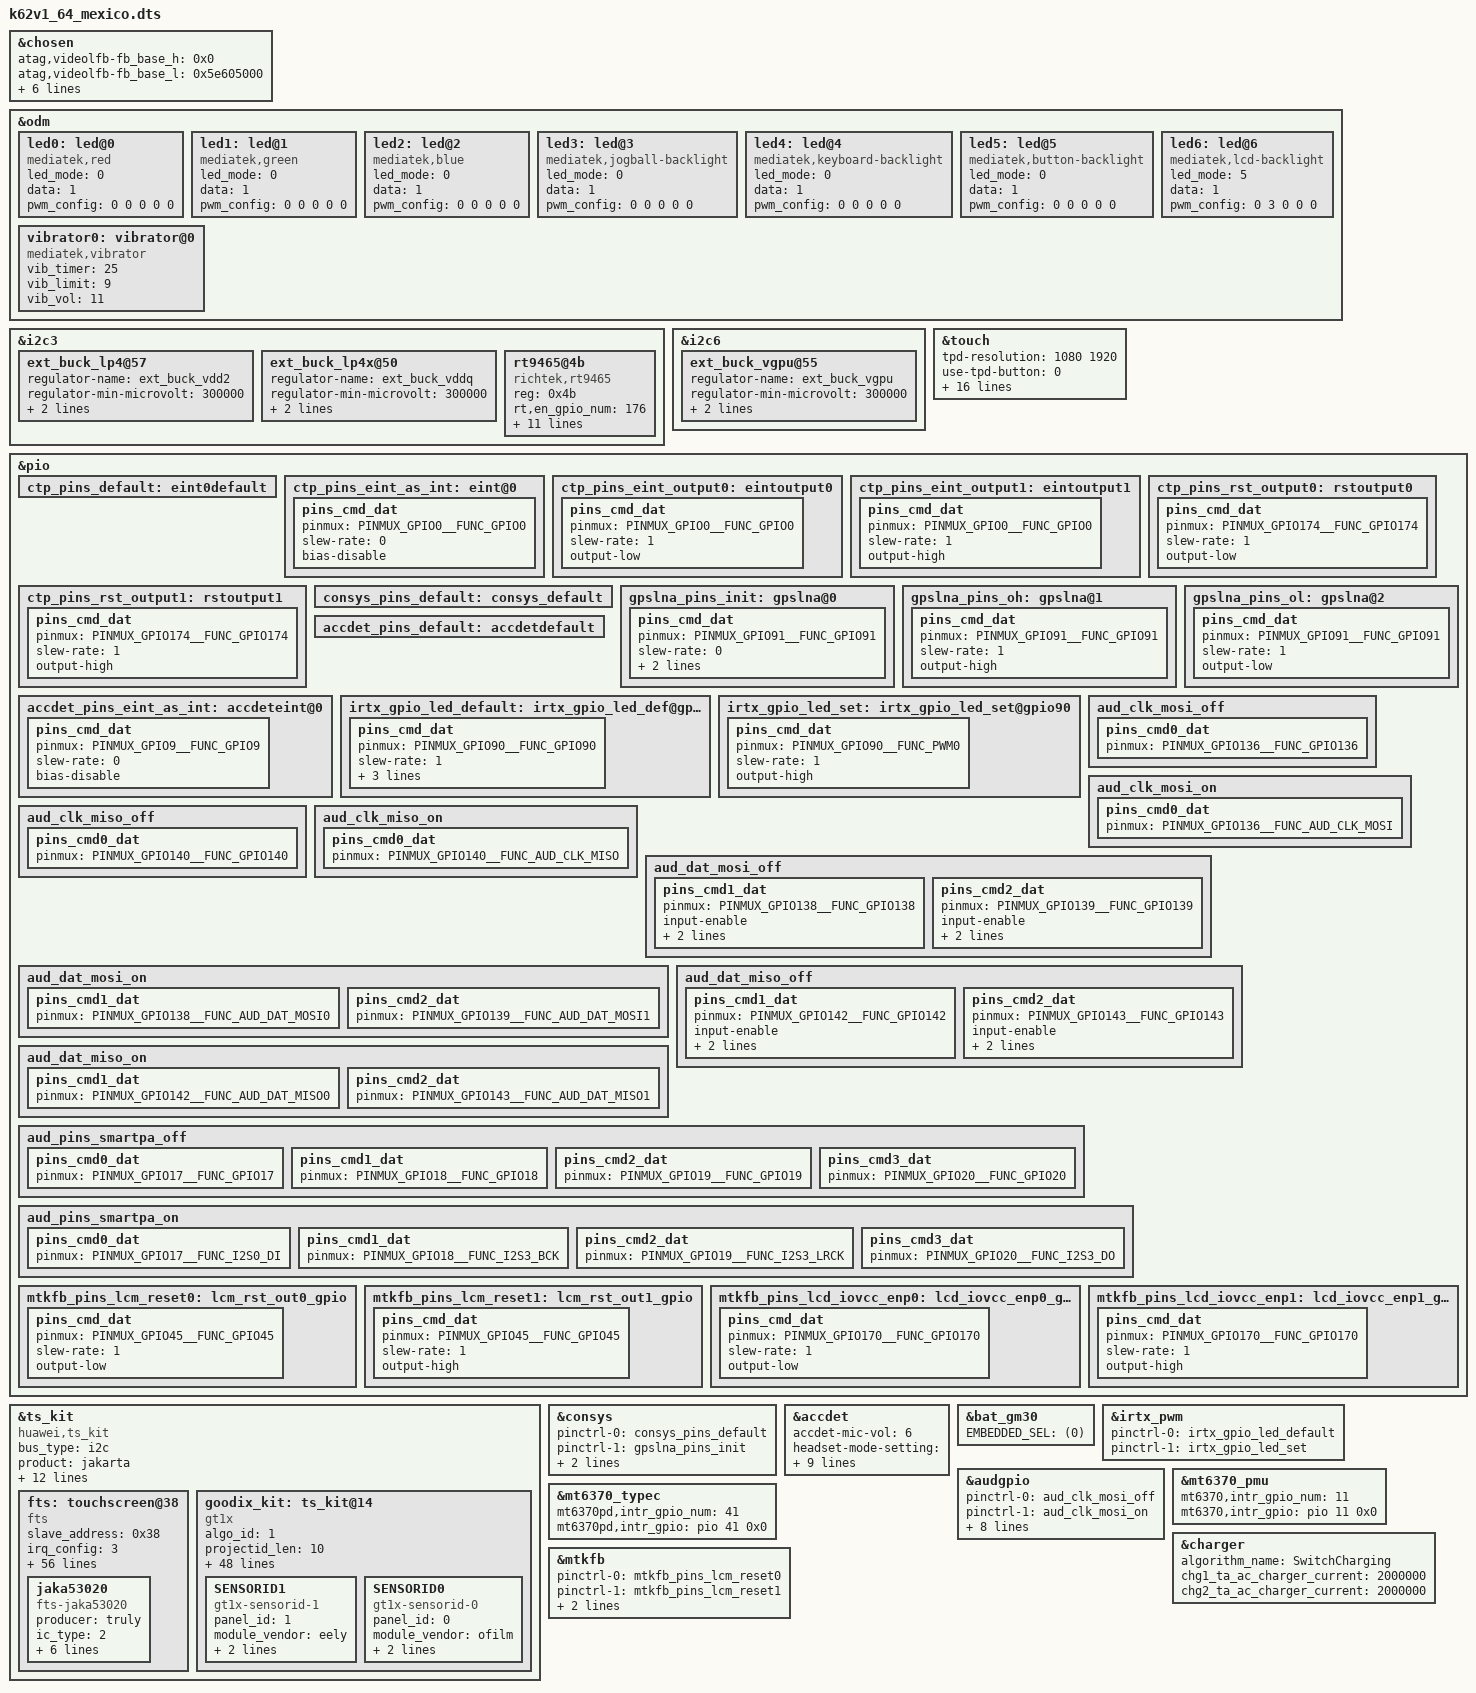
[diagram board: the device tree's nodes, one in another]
#include <dt-bindings/interrupt-controller/arm-gic.h>
#include <dt-bindings/interrupt-controller/irq.h>
#include <dt-bindings/pinctrl/mt6765-pinfunc.h>
#include <dt-bindings/clock/mt6765-clk.h>

/dts-v1/;
/plugin/;

#include "huawei-wifi.dtsi"

/* chosen */
&chosen {

	/* fpga may has no lk, we need to specify display info here */
	/* fb buffer is reserved using this dts by memory node above */
	atag,videolfb-fb_base_h = <0x0>;
	atag,videolfb-fb_base_l = <0x5e605000>;
	atag,videolfb-islcmfound = <1>;
	/* because no lk, so lcm is not inited */
	atag,videolfb-islcm_inited = <0>;
	atag,videolfb-fps= <6000>;
	atag,videolfb-vramSize= <0x017bb000>;
	atag,videolfb-lcmname= "nt35695B_fhd_dsi_cmd_auo_rt5081_drv";
};

&odm {
	led0:led@0 {
		compatible = "mediatek,red";
		led_mode = <0>;
		data = <1>;
		pwm_config = <0 0 0 0 0>;
	};
	led1:led@1 {
		compatible = "mediatek,green";
		led_mode = <0>;
		data = <1>;
		pwm_config = <0 0 0 0 0>;
	};
	led2:led@2 {
		compatible = "mediatek,blue";
		led_mode = <0>;
		data = <1>;
		pwm_config = <0 0 0 0 0>;
	};
	led3:led@3 {
		compatible = "mediatek,jogball-backlight";
		led_mode = <0>;
		data = <1>;
		pwm_config = <0 0 0 0 0>;
	};
	led4:led@4 {
		compatible = "mediatek,keyboard-backlight";
		led_mode = <0>;
		data = <1>;
		pwm_config = <0 0 0 0 0>;
	};
	led5:led@5 {
		compatible = "mediatek,button-backlight";
		led_mode = <0>;
		data = <1>;
		pwm_config = <0 0 0 0 0>;
	};
	led6:led@6 {
		compatible = "mediatek,lcd-backlight";
		led_mode = <5>;
		data = <1>;
		pwm_config = <0 3 0 0 0>;
	};
	vibrator0:vibrator@0 {
		compatible = "mediatek,vibrator";
		vib_timer = <25>;
		vib_limit = <9>;
		vib_vol= <11>;
	};
};

&i2c3 {
	ext_buck_lp4@57 {
		regulator-name ="ext_buck_vdd2";
		regulator-min-microvolt = <300000>;
		regulator-max-microvolt = <1300000>;
		vsel_pin = <0>;
	};

	ext_buck_lp4x@50 {
		regulator-name ="ext_buck_vddq";
		regulator-min-microvolt = <300000>;
		regulator-max-microvolt = <1300000>;
		vsel_pin = <1>;
	};
};

&i2c6 {
	ext_buck_vgpu@55 {
		regulator-name ="ext_buck_vgpu";
		regulator-min-microvolt = <300000>;
		regulator-max-microvolt = <1300000>;
		vsel_pin = <2>;
	};
};
/* TOUCH start */
&touch {
	tpd-resolution = <1080 1920>;
	use-tpd-button = <0>;
	tpd-key-num = <3>;
	tpd-key-local= <139 172 158 0>;
	tpd-key-dim-local = <90 883 100 40 230
				 883 100 40 370 883 100 40 0 0 0 0>;
	tpd-max-touch-num = <5>;
	tpd-filter-enable = <1>;
	tpd-filter-pixel-density = <146>;
	tpd-filter-custom-prameters = <0 0 0 0 0 0 0 0 0 0 0 0>;
	tpd-filter-custom-speed = <0 0 0>;
	pinctrl-names = "default", "state_eint_as_int", "state_eint_output0",
		"state_eint_output1", "state_rst_output0", "state_rst_output1";
	pinctrl-0 = <&ctp_pins_default>;
	pinctrl-1 = <&ctp_pins_eint_as_int>;
	pinctrl-2 = <&ctp_pins_eint_output0>;
	pinctrl-3 = <&ctp_pins_eint_output1>;
	pinctrl-4 = <&ctp_pins_rst_output0>;
	pinctrl-5 = <&ctp_pins_rst_output1>;
	status = "okay";
};
&pio {
	ctp_pins_default: eint0default {
	};
	ctp_pins_eint_as_int: eint@0 {
		pins_cmd_dat {
			pinmux = <PINMUX_GPIO0__FUNC_GPIO0>;
			slew-rate = <0>;
			bias-disable;
		};
	};
	ctp_pins_eint_output0: eintoutput0 {
		pins_cmd_dat {
			pinmux = <PINMUX_GPIO0__FUNC_GPIO0>;
			slew-rate = <1>;
			output-low;
		};
	};
	ctp_pins_eint_output1: eintoutput1 {
		pins_cmd_dat {
			pinmux = <PINMUX_GPIO0__FUNC_GPIO0>;
			slew-rate = <1>;
			output-high;
		};
	};
	ctp_pins_rst_output0: rstoutput0 {
		pins_cmd_dat {
			pinmux = <PINMUX_GPIO174__FUNC_GPIO174>;
			slew-rate = <1>;
			output-low;
		};
	};
	ctp_pins_rst_output1: rstoutput1 {
		pins_cmd_dat {
			pinmux = <PINMUX_GPIO174__FUNC_GPIO174>;
			slew-rate = <1>;
			output-high;
		};
	};
};
&ts_kit {
	status = "okay";
	compatible = "huawei,ts_kit";	/* Do not change value*/
	bus_type = "i2c";
	product = "jakarta";
	bus_id = <0>;
	has_virtualkey = <0>;
	debounce = <6 0>;
	interrupt-parent = <&pio>;
	interrupts = <0 2 0 0>;
	aft_enable = <0>;		/* aft algo switch. 1 - enabel, 0 - disable*/
	drv_stop_width = <0>;	/* always 0, can not config */
	lcd_width = <0>;		/* always 0, can not config */
	lcd_height = <0>;		/* always 0, can not config */
	need_i2c_hwlock = <0>;	/* for i2c both used by ap and sensorhub */
	register_charger_notifier = <0>;
	hide_plain_id = <0>;

	fts: touchscreen@38 {
		compatible = "fts";

		/* ts chip common config, parsed by paltform */
		/* hardware config part */
		slave_address = <0x38>;
		irq_config = <3>;

		/* base config */
		projectid_len = <10>; /* default 10 */
		ic_type = <2>;

		/* power config part */
		power_self_ctrl = <1>;
		ts-kit-iovdd-type = <1>;
		ts-kit-vcc-type = <1>;
		ts-kit-iovdd-value = <1800000>;
		ts-kit-vcc-value = <3000000>;
		vddio_default_on = <1>;
		ts-kit-iovdd-supply = <&mt_pmic_vs1_buck_reg>;  /* TODO:need parse by platform */
		ts-kit-vcc-supply = <&mt_pmic_vldo28_ldo_reg>; /* TODO:need parse by platform */

		/* pinctl config part */
		pinctrl-names = "default", "state_eint_as_int", "state_eint_output0",
			"state_eint_output1", "state_rst_output0", "state_rst_output1";
		pinctrl-0 = <&ctp_pins_default>;
		pinctrl-1 = <&ctp_pins_eint_as_int>;
		pinctrl-2 = <&ctp_pins_eint_output0>;
		pinctrl-3 = <&ctp_pins_eint_output1>;
		pinctrl-4 = <&ctp_pins_rst_output0>;
		pinctrl-5 = <&ctp_pins_rst_output1>;

		/* input config part */
		x_max = <720>;
		y_max = <1560>;
		x_max_mt = <720>;
		y_max_mt = <1560>;
		flip_x = <1>;
		flip_y = <1>;

		/* feature config part */
		parade,is_parade_solution = <0>;
		parade,direct_proc_cmd = <0>;
		parade,sleep_in_mode = <0>;
		roi_supported = <0>;
		glove_supported = <0>;
		holster_supported = <0>;
		pen_support = <0>;
		support_3d_func = <0>;
		charger_supported = <0>;
		check_bulcked = <0>;
		support_aft = <0>;
		use_lcdkit_power_notify = <1>;
		fp_tp_report_touch_minor_event = <0>;
		algo_id = <1>; /* 0 - not use driver algo 1 - algo t1 */
		need_wd_check_status = <0>;
		check_status_watchdog_timeout = <0>;
		touch_switch_flag = <0>;
		get_brightness_info_flag = <0>;
		has_virtualkey = <0>;
		lcd_full = <0>;
		provide_panel_id_support = <0>;
		chip_id = <0x54>;
		hard_reset_delay = <200>;
		erase_min_delay = <1350>;
		calc_crc_delay = <300>;
		reboot_delay = <300>;
		erase_query_delay = <50>;
		write_flash_query_times = <30>;
		read_ecc_query_times = <100>;
		erase_flash_query_times = <15>;
		upgrade_loop_times = <5>;
		pram_projectid_addr = <0xd7a0>;
		rawdata_newformatflag = <1>;
		only_open_once_captest_threshold = <1>;
		jaka53020{
			producer = "truly";
			ic_type = <2>;
			compatible = "fts-jaka53020";
			row_column_delta_test = <0>;
			lcd_noise_data_test = <1>;
			row_column_delta_test_point_by_point = <1>;
			threshold,point_by_point_judge = <1>;
			threshold,in_csv_file = <1>;
			provide_panel_id_suppot = <1>;

			/* chip private config */
		};
	};
	goodix_kit: ts_kit@14 {
		compatible = "gt1x";
		algo_id = <1>;
		projectid_len = <10>; /* default 10 */

		/* pinctl config part */
		pinctrl-names = "default", "state_eint_as_int", "state_eint_output0",
			"state_eint_output1", "state_rst_output0", "state_rst_output1";
		pinctrl-0 = <&ctp_pins_default>;
		pinctrl-1 = <&ctp_pins_eint_as_int>;
		pinctrl-2 = <&ctp_pins_eint_output0>;
		pinctrl-3 = <&ctp_pins_eint_output1>;
		pinctrl-4 = <&ctp_pins_rst_output0>;
		pinctrl-5 = <&ctp_pins_rst_output1>;

		/* input config part */
		x_max = <720>;
		y_max = <1560>;
		x_max_mt = <720>;
		y_max_mt = <1560>;
		flip_x = <1>;
		flip_y = <1>;

		/* power config part */
		power_self_ctrl = <1>;
		ts-kit-iovdd-type = <1>;
		ts-kit-vcc-type = <1>;
		ts-kit-iovdd-value = <1800000>;
		ts-kit-vcc-value = <3000000>;
		vddio_default_on = <1>;
		ts-kit-iovdd-supply = <&mt_pmic_vs1_buck_reg>;  /* TODO:need parse by platform */
		ts-kit-vcc-supply = <&mt_pmic_vldo28_ldo_reg>; /* TODO:need parse by platform */

		slave_address = <0x14>;
		irq_config = <3>;/* 0 - LOW LEVEL  1 - HIGH LEVEL  2 - RAISE EDGE  3 - FALL EDGE*/

		roi_data_size = <7 7>; /* row and colume*/
		project_id = "JAKA54000";
		chip_name = "1158"; /* GT1151Q */
		module_vendor = "ofilm";

		rawdata_newformatflag = <1>;
		/* feature config part */
		parade,is_parade_solution = <0>;
		parade,direct_proc_cmd = <0>;
		parade,sleep_in_mode = <0>;
		roi_supported = <0>;
		glove_supported = <0>;
		holster_supported = <0>;
		pen_support = <0>;
		support_3d_func = <0>;
		charger_supported = <0>;
		check_bulcked = <0>;
		support_aft = <0>;
		tools_support = <1>; /* support GTP tools APK ,0:no support; 1: support*/
		easy_wakeup_supported = <0>;
		ic_type = <0>; /* 0: 9PT, 1: 9P*/
		gt1x_test_limit = <1>;
		use_lcdkit_power_notify = <1>;
		support_get_tp_color = <0>;
		fw_only_depend_on_lcd = <0>;
		gt1x_edge_add = <0x81A1>;
		gt1x_support_edge_xyer = <1>;
		only_open_once_captest_threshold = <1>;
		SENSORID1 {
			compatible = "gt1x-sensorid-1";
			panel_id = <1>;
			module_vendor = "eely";
			provide_panel_id_suppot = <1>;
			project_id = "JAKA54010";
		};
		SENSORID0 {
			compatible = "gt1x-sensorid-0";
			panel_id = <0>;
			module_vendor = "ofilm";
			provide_panel_id_suppot = <1>;
			project_id = "JAKA54000";
		};
	};
};
/* TOUCH end */

/* CONSYS GPIO standardization */
&pio {
	consys_pins_default: consys_default {
	};
	gpslna_pins_init: gpslna@0 {
		pins_cmd_dat {
			pinmux = <PINMUX_GPIO91__FUNC_GPIO91>;
			slew-rate = <0>;
			bias-disable;
			output-low;
		};
	};
	gpslna_pins_oh: gpslna@1 {
		pins_cmd_dat {
			pinmux = <PINMUX_GPIO91__FUNC_GPIO91>;
			slew-rate = <1>;
			output-high;
		};
	};
	gpslna_pins_ol: gpslna@2 {
		pins_cmd_dat {
			pinmux = <PINMUX_GPIO91__FUNC_GPIO91>;
			slew-rate = <1>;
			output-low;
		};
	};
};
&consys {
	pinctrl-names = "default", "gps_lna_state_init",
		"gps_lna_state_oh", "gps_lna_state_ol";
	pinctrl-0 = <&consys_pins_default>;
	pinctrl-1 = <&gpslna_pins_init>;
	pinctrl-2 = <&gpslna_pins_oh>;
	pinctrl-3 = <&gpslna_pins_ol>;
	status = "okay";
};
/* CONSYS end */

/* accdet start */
&accdet {
	accdet-mic-vol = <6>;
	headset-mode-setting = <0x500 0x500 1 0x1f0 0x800 0x800 0x20 0x44>;
	accdet-plugout-debounce = <1>;
	accdet-mic-mode = <1>;
	headset-eint-level-pol = <8>;
	headset-three-key-threshold = <0 80 220 400>;
	headset-three-key-threshold-CDD = <0 121 192 600>;
	headset-four-key-threshold = <0 58 121 192 400>;
	pinctrl-names = "default", "state_eint_as_int";
	pinctrl-0 = <&accdet_pins_default>;
	pinctrl-1 = <&accdet_pins_eint_as_int>;
	status = "okay";
};
&pio {
	accdet_pins_default: accdetdefault {
	};
	accdet_pins_eint_as_int: accdeteint@0 {
		pins_cmd_dat {
			pinmux = <PINMUX_GPIO9__FUNC_GPIO9>;
			slew-rate = <0>;
			bias-disable;
		};
	};
};
/* accdet end */

/* FINGERPRINT start */
/*
&spi0 {
	#address-cells = <1>;
	#size-cells = <0>;
	fingerprint@0 {
		compatible = "goodix,goodix-fp";
		reg = <0>;
		spi-max-frequency = <8000000>;
		netlink-event = <30>;
		status = "okay";
	};
};

&goodix_fp {
	pinctrl-names = "default", "reset_high", "reset_low";
	pinctrl-0 = <&fingerprint_default>;
	pinctrl-1 = <&fingerprint_reset_high>;
	pinctrl-2 = <&fingerprint_reset_low>;
	status = "okay";
};

&pio {
	fingerprint_default: state_default {
	};
	fingerprint_reset_high: state_reset_high {
		pins_cmd_dat {
			pinmux = <PINMUX_GPIO172__FUNC_GPIO172>;
			slew-rate = <1>;
			output-high;
		};
	};
	fingerprint_reset_low: state_reset_low {
		pins_cmd_dat {
			pinmux = <PINMUX_GPIO172__FUNC_GPIO172>;
			slew-rate = <1>;
			output-low;
		};
	};
};*/
/* FINGERPRINT end */

/* battery end */
&bat_gm30 {
	EMBEDDED_SEL = <(0)>;
};
/* battery end */

/* IRTX GPIO end */
&irtx_pwm {
	pinctrl-names = "irtx_gpio_led_default", "irtx_gpio_led_set";
	pinctrl-0 = <&irtx_gpio_led_default>;
	pinctrl-1 = <&irtx_gpio_led_set>;
	status = "okay";
};
&pio {
	irtx_gpio_led_default:irtx_gpio_led_def@gpio90 {
		pins_cmd_dat {
			pinmux = <PINMUX_GPIO90__FUNC_GPIO90>;
			slew-rate = <1>;
			bias-disable;
			output-low;
			input-schmitt-enable = <0>;
		};
	};

	irtx_gpio_led_set:irtx_gpio_led_set@gpio90 {
		pins_cmd_dat {
			pinmux = <PINMUX_GPIO90__FUNC_PWM0>;
			slew-rate = <1>;
			output-high;
		};
	};
};
/* IRTX GPIO Settings -End */

/* AUDIO GPIO standardization */
&audgpio {
	pinctrl-names = "aud_clk_mosi_off",
			"aud_clk_mosi_on",
			"aud_clk_miso_off",
			"aud_clk_miso_on",
			"aud_dat_mosi_off",
			"aud_dat_mosi_on",
			"aud_dat_miso_off",
			"aud_dat_miso_on",
			"aud_smartpa_off",
			"aud_smartpa_on";
	pinctrl-0 = <&aud_clk_mosi_off>;
	pinctrl-1 = <&aud_clk_mosi_on>;
	pinctrl-2 = <&aud_clk_miso_off>;
	pinctrl-3 = <&aud_clk_miso_on>;
	pinctrl-4 = <&aud_dat_mosi_off>;
	pinctrl-5 = <&aud_dat_mosi_on>;
	pinctrl-6 = <&aud_dat_miso_off>;
	pinctrl-7 = <&aud_dat_miso_on>;
	pinctrl-8 = <&aud_pins_smartpa_off>;
	pinctrl-9 = <&aud_pins_smartpa_on>;
	status = "okay";
};

&pio {
	aud_clk_mosi_off: aud_clk_mosi_off {
		pins_cmd0_dat {
			pinmux = <PINMUX_GPIO136__FUNC_GPIO136>;
		};
	};

	aud_clk_mosi_on: aud_clk_mosi_on {
		pins_cmd0_dat {
			pinmux = <PINMUX_GPIO136__FUNC_AUD_CLK_MOSI>;
		};
	};

	aud_clk_miso_off: aud_clk_miso_off {
		pins_cmd0_dat {
			pinmux = <PINMUX_GPIO140__FUNC_GPIO140>;
		};
	};

	aud_clk_miso_on: aud_clk_miso_on {
		pins_cmd0_dat {
			pinmux = <PINMUX_GPIO140__FUNC_AUD_CLK_MISO>;
		};
	};

	aud_dat_mosi_off: aud_dat_mosi_off {
		pins_cmd1_dat {
			pinmux = <PINMUX_GPIO138__FUNC_GPIO138>;
			input-enable;
			slew-rate = <0>;
			bias-disable;
		};
		pins_cmd2_dat {
			pinmux = <PINMUX_GPIO139__FUNC_GPIO139>;
			input-enable;
			slew-rate = <0>;
			bias-disable;
		};
	};

	aud_dat_mosi_on: aud_dat_mosi_on {
		pins_cmd1_dat {
			pinmux = <PINMUX_GPIO138__FUNC_AUD_DAT_MOSI0>;
		};
		pins_cmd2_dat {
			pinmux = <PINMUX_GPIO139__FUNC_AUD_DAT_MOSI1>;
		};
	};

	aud_dat_miso_off: aud_dat_miso_off {
		pins_cmd1_dat {
			pinmux = <PINMUX_GPIO142__FUNC_GPIO142>;
			input-enable;
			slew-rate = <0>;
			bias-disable;
		};
		pins_cmd2_dat {
			pinmux = <PINMUX_GPIO143__FUNC_GPIO143>;
			input-enable;
			slew-rate = <0>;
			bias-disable;
		};
	};

	aud_dat_miso_on: aud_dat_miso_on {
		pins_cmd1_dat {
			pinmux = <PINMUX_GPIO142__FUNC_AUD_DAT_MISO0>;
		};
		pins_cmd2_dat {
			pinmux = <PINMUX_GPIO143__FUNC_AUD_DAT_MISO1>;
		};
	};

	aud_pins_smartpa_off: aud_pins_smartpa_off {
		pins_cmd0_dat {
			pinmux = <PINMUX_GPIO17__FUNC_GPIO17>;
		};
		pins_cmd1_dat {
			pinmux = <PINMUX_GPIO18__FUNC_GPIO18>;
		};
		pins_cmd2_dat {
			pinmux = <PINMUX_GPIO19__FUNC_GPIO19>;
		};
		pins_cmd3_dat {
			pinmux = <PINMUX_GPIO20__FUNC_GPIO20>;
		};
	};

	aud_pins_smartpa_on: aud_pins_smartpa_on {
		pins_cmd0_dat {
			pinmux = <PINMUX_GPIO17__FUNC_I2S0_DI>;
		};
		pins_cmd1_dat {
			pinmux = <PINMUX_GPIO18__FUNC_I2S3_BCK>;
		};
		pins_cmd2_dat {
			pinmux = <PINMUX_GPIO19__FUNC_I2S3_LRCK>;
		};
		pins_cmd3_dat {
			pinmux = <PINMUX_GPIO20__FUNC_I2S3_DO>;
		};
	};
};
/* AUDIO end */

&mt6370_pmu {
	mt6370,intr_gpio_num = <11>; /* direct defined GPIO num */
	mt6370,intr_gpio = <&pio 11 0x0>;
};

&mt6370_typec {
	mt6370pd,intr_gpio_num = <41>; /* direct defined GPIO num */
	mt6370pd,intr_gpio = <&pio 41 0x0>;
};

&charger {
	algorithm_name = "SwitchCharging";
	chg1_ta_ac_charger_current = <2000000>;
	chg2_ta_ac_charger_current = <2000000>;
};

&i2c3 {
	rt9465@4b {
		compatible = "richtek,rt9465";
		reg = <0x4b>;
		status = "okay";
		rt,en_gpio_num = <176>;
		rt,en_gpio = <&pio 176 0x0>;
		rt,intr_gpio_num = <23>; /* direct defined GPIO num */
		rt,intr_gpio = <&pio 23 0x0>;
		interrupt-names = "wdtmri";
		charger_name = "secondary_chg";
		ichg = <1500000>; /* uA */
		mivr = <4500000>; /* uV */
		cv = <4550000>; /* uV */
		ieoc = <700000>; /* uA */
		safety_timer = <12>; /* hour */
		en_st; /* safety timer */
		/* en_te; */
		en_wdt;
	};
};


/* DISPSYS GPIO standardization */
&pio {
	mtkfb_pins_lcm_reset0: lcm_rst_out0_gpio {
		pins_cmd_dat {
			pinmux = <PINMUX_GPIO45__FUNC_GPIO45>;
			slew-rate = <1>;
			output-low;
		};
	};

	mtkfb_pins_lcm_reset1: lcm_rst_out1_gpio {
		pins_cmd_dat {
			pinmux = <PINMUX_GPIO45__FUNC_GPIO45>;
			slew-rate = <1>;
			output-high;
		};
	};

	mtkfb_pins_lcd_iovcc_enp0: lcd_iovcc_enp0_gpio {
		pins_cmd_dat {
			pinmux = <PINMUX_GPIO170__FUNC_GPIO170>;
			slew-rate = <1>;
			output-low;
		};
	};

	mtkfb_pins_lcd_iovcc_enp1: lcd_iovcc_enp1_gpio {
		pins_cmd_dat {
			pinmux = <PINMUX_GPIO170__FUNC_GPIO170>;
			slew-rate = <1>;
			output-high;
		};
	};
};

&mtkfb {
	pinctrl-names = "lcm_rst_out0_gpio", "lcm_rst_out1_gpio", "lcd_iovcc_enp0_gpio", "lcd_iovcc_enp1_gpio";
	pinctrl-0 = <&mtkfb_pins_lcm_reset0>;
	pinctrl-1 = <&mtkfb_pins_lcm_reset1>;
	pinctrl-2 = <&mtkfb_pins_lcd_iovcc_enp0>;
	pinctrl-3 = <&mtkfb_pins_lcd_iovcc_enp1>;
	status = "okay";
};

#include <k62v1_64_mexico/cust.dtsi>
#include "huawei-mt6765-camera-demo62.dtsi"
/*End of this file, DO NOT ADD ANYTHING HERE*/
